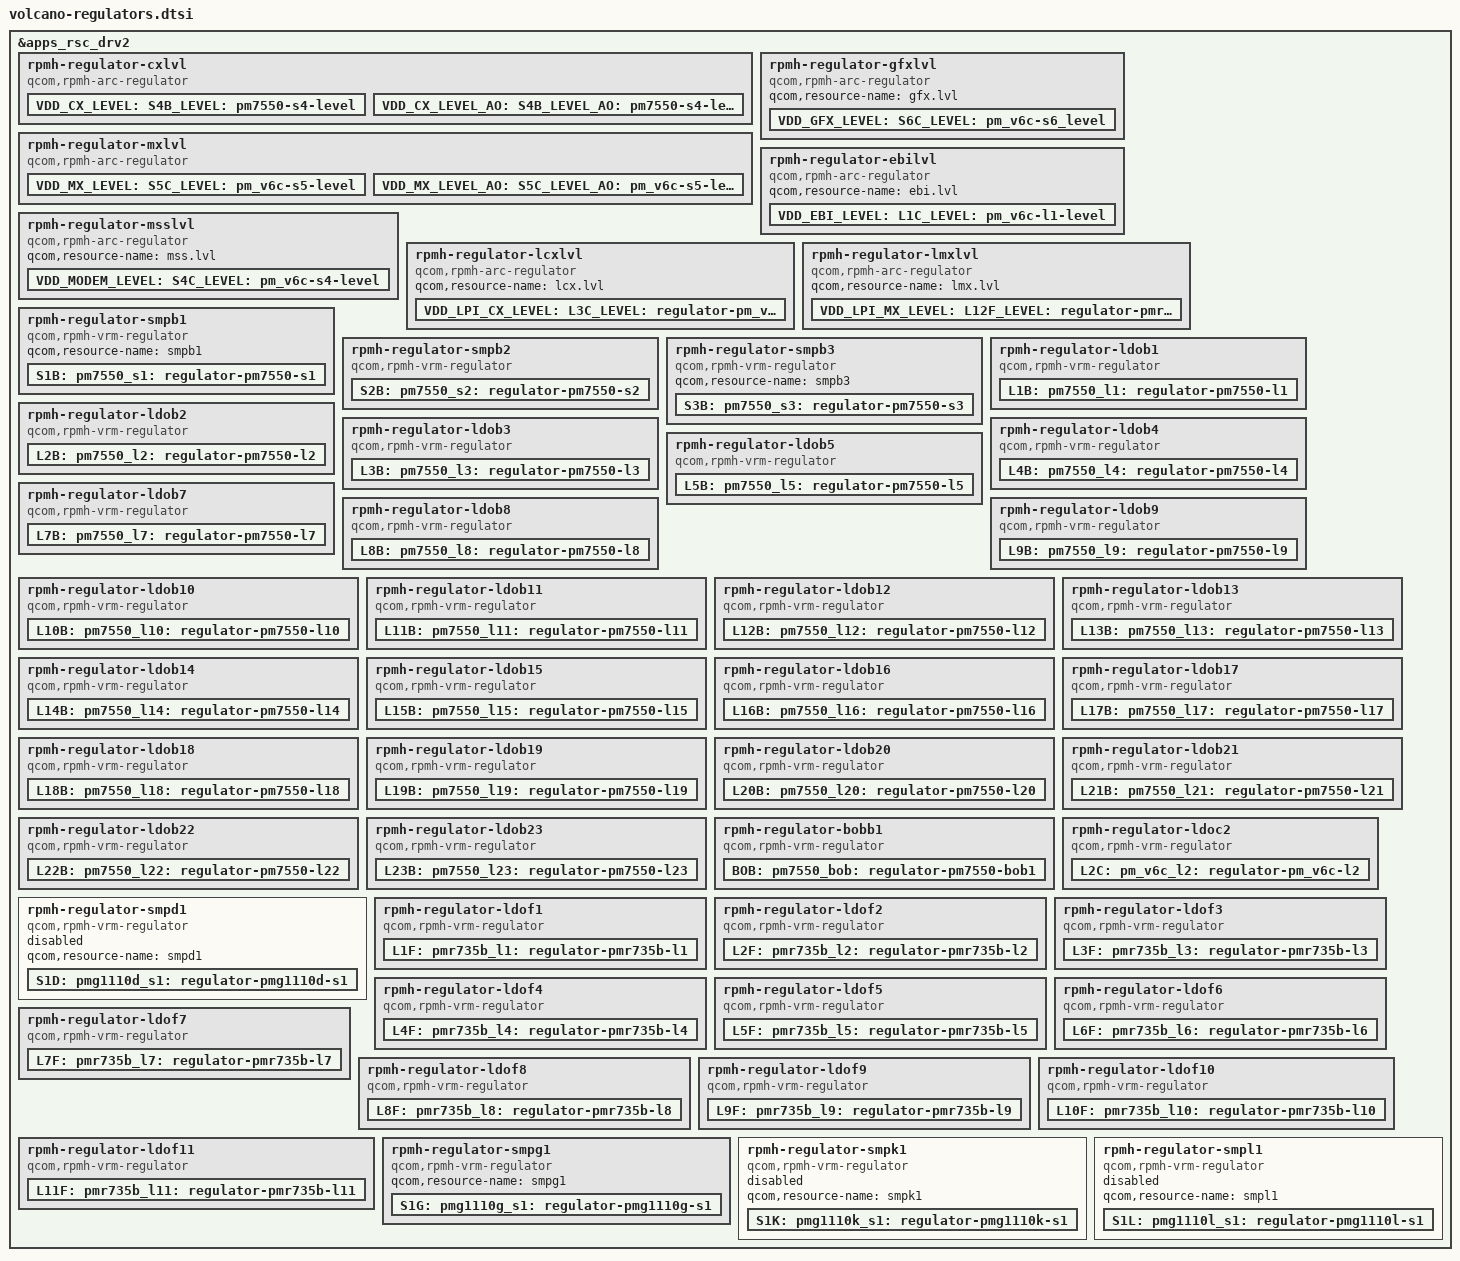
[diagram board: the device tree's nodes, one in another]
#include <dt-bindings/regulator/qcom,rpmh-regulator-levels.h>

&apps_rsc_drv2 {
	rpmh-regulator-cxlvl {
		compatible = "qcom,rpmh-arc-regulator";
		qcom,resource-name = "cx.lvl";
		proxy-supply = <&VDD_CX_LEVEL>;

		VDD_CX_LEVEL:
		S4B_LEVEL:
		pm7550_s4_level: pm7550-s4-level {
			regulator-name = "pm7550_s4_level";
			qcom,set = <RPMH_REGULATOR_SET_ALL>;
			qcom,proxy-consumer-enable;
			qcom,proxy-consumer-voltage = <RPMH_REGULATOR_LEVEL_TURBO
							RPMH_REGULATOR_LEVEL_MAX>;
			regulator-min-microvolt =
				<RPMH_REGULATOR_LEVEL_RETENTION>;
			regulator-max-microvolt = <RPMH_REGULATOR_LEVEL_MAX>;
			qcom,init-voltage-level =
				<RPMH_REGULATOR_LEVEL_TURBO>;
		};

		VDD_CX_LEVEL_AO:
		S4B_LEVEL_AO:
		pm7550_s4_level_ao: pm7550-s4-level-ao {
			regulator-name = "pm7550_s4_level_ao";
			qcom,set = <RPMH_REGULATOR_SET_ACTIVE>;
			regulator-min-microvolt =
				<RPMH_REGULATOR_LEVEL_RETENTION>;
			regulator-max-microvolt = <RPMH_REGULATOR_LEVEL_MAX>;
			qcom,init-voltage-level =
				<RPMH_REGULATOR_LEVEL_RETENTION>;
		};
	};

	rpmh-regulator-mxlvl {
		compatible = "qcom,rpmh-arc-regulator";
		qcom,resource-name = "mx.lvl";
		proxy-supply = <&VDD_MX_LEVEL>;

		VDD_MX_LEVEL:
		S5C_LEVEL:
		pm_v6c_s5_level: pm_v6c-s5-level {
			regulator-name = "pm_v6c_s5_level";
			qcom,set = <RPMH_REGULATOR_SET_ALL>;
			qcom,proxy-consumer-enable;
			qcom,proxy-consumer-voltage = <RPMH_REGULATOR_LEVEL_TURBO
							RPMH_REGULATOR_LEVEL_MAX>;
			regulator-min-microvolt =
				<RPMH_REGULATOR_LEVEL_RETENTION>;
			regulator-max-microvolt = <RPMH_REGULATOR_LEVEL_MAX>;
			qcom,init-voltage-level =
				<RPMH_REGULATOR_LEVEL_RETENTION>;
		};

		VDD_MX_LEVEL_AO:
		S5C_LEVEL_AO:
		pm_v6c_s5_level_ao: pm_v6c-s5-level-ao {
			regulator-name = "pm_v6c_s5_level_ao";
			qcom,set = <RPMH_REGULATOR_SET_ACTIVE>;
			regulator-min-microvolt =
				<RPMH_REGULATOR_LEVEL_RETENTION>;
			regulator-max-microvolt = <RPMH_REGULATOR_LEVEL_MAX>;
			qcom,init-voltage-level =
				<RPMH_REGULATOR_LEVEL_RETENTION>;
		};
	};

	rpmh-regulator-gfxlvl {
		compatible = "qcom,rpmh-arc-regulator";
		qcom,resource-name = "gfx.lvl";

		VDD_GFX_LEVEL:
		S6C_LEVEL:
		pm_v6c_s6_level: pm_v6c-s6_level {
			regulator-name = "pm_v6c_s6_level";
			qcom,set = <RPMH_REGULATOR_SET_ALL>;
			regulator-min-microvolt =
					<RPMH_REGULATOR_LEVEL_RETENTION>;
			regulator-max-microvolt = <RPMH_REGULATOR_LEVEL_MAX>;
			qcom,init-voltage-level = <RPMH_REGULATOR_LEVEL_TURBO>;
		};
	};

	rpmh-regulator-ebilvl {
		compatible = "qcom,rpmh-arc-regulator";
		qcom,resource-name = "ebi.lvl";

		VDD_EBI_LEVEL:
		L1C_LEVEL:
		pm_v6c_l1_level: pm_v6c-l1-level {
			regulator-name = "pm_v6c_l1_level";
			qcom,set = <RPMH_REGULATOR_SET_ALL>;
			regulator-min-microvolt =
				<RPMH_REGULATOR_LEVEL_RETENTION>;
			regulator-max-microvolt = <RPMH_REGULATOR_LEVEL_MAX>;
			qcom,init-voltage-level =
				<RPMH_REGULATOR_LEVEL_TURBO>;
		};
	};

	rpmh-regulator-msslvl {
		compatible = "qcom,rpmh-arc-regulator";
		qcom,resource-name = "mss.lvl";

		VDD_MODEM_LEVEL:
		S4C_LEVEL:
		pm_v6c_s4_level: pm_v6c-s4-level {
			regulator-name = "pm_v6c_s4_level";
			qcom,set = <RPMH_REGULATOR_SET_ALL>;
			regulator-min-microvolt =
				<RPMH_REGULATOR_LEVEL_RETENTION>;
			regulator-max-microvolt = <RPMH_REGULATOR_LEVEL_MAX>;
			qcom,init-voltage-level =
				<RPMH_REGULATOR_LEVEL_RETENTION>;
		};
	};

	rpmh-regulator-lcxlvl {
		compatible = "qcom,rpmh-arc-regulator";
		qcom,resource-name = "lcx.lvl";

		VDD_LPI_CX_LEVEL:
		L3C_LEVEL:
		pm_v6c_l3_level: regulator-pm_v6c-l3-level {
			regulator-name = "pm_v6c_l3_level";
			qcom,set = <RPMH_REGULATOR_SET_ALL>;
			regulator-min-microvolt =
				<RPMH_REGULATOR_LEVEL_RETENTION>;
			regulator-max-microvolt = <RPMH_REGULATOR_LEVEL_MAX>;
			qcom,init-voltage-level =
				<RPMH_REGULATOR_LEVEL_RETENTION>;
		};
	};

	rpmh-regulator-lmxlvl {
		compatible = "qcom,rpmh-arc-regulator";
		qcom,resource-name = "lmx.lvl";

		VDD_LPI_MX_LEVEL:
		L12F_LEVEL:
		pmr735b_l12_level: regulator-pmr735b-l12-level {
			regulator-name = "pmr735b_l12_level";
			qcom,set = <RPMH_REGULATOR_SET_ALL>;
			regulator-min-microvolt =
				<RPMH_REGULATOR_LEVEL_RETENTION>;
			regulator-max-microvolt = <RPMH_REGULATOR_LEVEL_MAX>;
			qcom,init-voltage-level =
				<RPMH_REGULATOR_LEVEL_RETENTION>;
		};
	};

	rpmh-regulator-smpb1 {
		compatible = "qcom,rpmh-vrm-regulator";
		qcom,resource-name = "smpb1";

		S1B:
		pm7550_s1: regulator-pm7550-s1 {
			regulator-name = "pm7550_s1";
			qcom,set = <RPMH_REGULATOR_SET_ALL>;
			regulator-min-microvolt = <1800000>;
			regulator-max-microvolt = <2080000>;
			qcom,init-voltage = <1872000>;
		};
	};

	rpmh-regulator-smpb2 {
		compatible = "qcom,rpmh-vrm-regulator";
		qcom,resource-name = "smpb2";
		qcom,regulator-type = "pmic5-ftsmps";
		qcom,supported-modes = <RPMH_REGULATOR_MODE_RET
			 RPMH_REGULATOR_MODE_HPM>;
		qcom,mode-threshold-currents = <0 200000>;

		S2B:
		pm7550_s2: regulator-pm7550-s2 {
			regulator-name = "pm7550_s2";
			qcom,set = <RPMH_REGULATOR_SET_ALL>;
			regulator-min-microvolt = <1256000>;
			regulator-max-microvolt = <1408000>;
			qcom,init-voltage = <1256000>;
			qcom,init-mode = <RPMH_REGULATOR_MODE_HPM>;
		};
	};

	rpmh-regulator-smpb3 {
		compatible = "qcom,rpmh-vrm-regulator";
		qcom,resource-name = "smpb3";

		S3B:
		pm7550_s3: regulator-pm7550-s3 {
			regulator-name = "pm7550_s3";
			qcom,set = <RPMH_REGULATOR_SET_ALL>;
			regulator-min-microvolt = <880000>;
			regulator-max-microvolt = <1040000>;
			qcom,init-voltage = <972000>;
		};
	};

	rpmh-regulator-ldob1 {
		compatible = "qcom,rpmh-vrm-regulator";
		qcom,resource-name = "ldob1";
		qcom,regulator-type = "pmic5-ldo";
		qcom,supported-modes =
			<RPMH_REGULATOR_MODE_LPM
			RPMH_REGULATOR_MODE_HPM>;
		qcom,mode-threshold-currents = <0 30000>;

		L1B:
		pm7550_l1: regulator-pm7550-l1 {
			regulator-name = "pm7550_l1";
			qcom,set = <RPMH_REGULATOR_SET_ALL>;
			regulator-min-microvolt = <1800000>;
			regulator-max-microvolt = <1800000>;
			qcom,init-voltage = <1800000>;
			qcom,init-mode = <RPMH_REGULATOR_MODE_LPM>;
			regulator-always-on;
		};
	};

	rpmh-regulator-ldob2 {
		compatible = "qcom,rpmh-vrm-regulator";
		qcom,resource-name = "ldob2";
		qcom,regulator-type = "pmic5-ldo";
		qcom,supported-modes =
			<RPMH_REGULATOR_MODE_LPM
			RPMH_REGULATOR_MODE_HPM>;
		qcom,mode-threshold-currents = <0 30000>;
		proxy-supply = <&L2B>;

		L2B:
		pm7550_l2: regulator-pm7550-l2 {
			regulator-name = "pm7550_l2";
			qcom,set = <RPMH_REGULATOR_SET_ALL>;
			regulator-min-microvolt = <880000>;
			regulator-max-microvolt = <912000>;
			qcom,init-voltage = <880000>;
			qcom,init-mode = <RPMH_REGULATOR_MODE_HPM>;
			qcom,proxy-consumer-enable;
			qcom,proxy-consumer-current = <98000>;
		};
	};

	rpmh-regulator-ldob3 {
		compatible = "qcom,rpmh-vrm-regulator";
		qcom,resource-name = "ldob3";
		qcom,regulator-type = "pmic5-ldo";
		qcom,supported-modes =
			<RPMH_REGULATOR_MODE_LPM
			RPMH_REGULATOR_MODE_HPM>;
		qcom,mode-threshold-currents = <0 30000>;

		L3B:
		pm7550_l3: regulator-pm7550-l3 {
			regulator-name = "pm7550_l3";
			qcom,set = <RPMH_REGULATOR_SET_ALL>;
			regulator-min-microvolt = <880000>;
			regulator-max-microvolt = <912000>;
			qcom,init-voltage = <880000>;
			qcom,init-mode = <RPMH_REGULATOR_MODE_HPM>;
		};
	};

	rpmh-regulator-ldob4 {
		compatible = "qcom,rpmh-vrm-regulator";
		qcom,resource-name = "ldob4";
		qcom,regulator-type = "pmic5-ldo";
		qcom,supported-modes =
			<RPMH_REGULATOR_MODE_LPM
			RPMH_REGULATOR_MODE_HPM>;
		qcom,mode-threshold-currents = <0 30000>;
		proxy-supply = <&L4B>;

		L4B:
		pm7550_l4: regulator-pm7550-l4 {
			regulator-name = "pm7550_l4";
			qcom,set = <RPMH_REGULATOR_SET_ALL>;
			regulator-min-microvolt = <1200000>;
			regulator-max-microvolt = <1200000>;
			qcom,init-voltage = <1200000>;
			qcom,init-mode = <RPMH_REGULATOR_MODE_HPM>;
			qcom,proxy-consumer-enable;
			qcom,proxy-consumer-current = <16600>;
		};
	};

	rpmh-regulator-ldob5 {
		compatible = "qcom,rpmh-vrm-regulator";
		qcom,resource-name = "ldob5";
		qcom,regulator-type = "pmic5-ldo";
		qcom,supported-modes =
			<RPMH_REGULATOR_MODE_RET
			 RPMH_REGULATOR_MODE_LPM
			 RPMH_REGULATOR_MODE_HPM>;
		qcom,mode-threshold-currents = <0 10000 30000>;

		L5B:
		pm7550_l5: regulator-pm7550-l5 {
			regulator-name = "pm7550_l5";
			qcom,set = <RPMH_REGULATOR_SET_ALL>;
			regulator-min-microvolt = <1200000>;
			regulator-max-microvolt = <1200000>;
			qcom,init-voltage = <1200000>;
			qcom,init-mode = <RPMH_REGULATOR_MODE_LPM>;
			regulator-always-on;
		};
	};

	rpmh-regulator-ldob7 {
		compatible = "qcom,rpmh-vrm-regulator";
		qcom,resource-name = "ldob7";
		qcom,regulator-type = "pmic5-ldo";
		qcom,supported-modes =
			<RPMH_REGULATOR_MODE_LPM
			RPMH_REGULATOR_MODE_HPM>;
		qcom,mode-threshold-currents = <0 30000>;

		L7B:
		pm7550_l7: regulator-pm7550-l7 {
			regulator-name = "pm7550_l7";
			qcom,set = <RPMH_REGULATOR_SET_ALL>;
			regulator-min-microvolt = <1800000>;
			regulator-max-microvolt = <1800000>;
			qcom,init-voltage = <1800000>;
			qcom,init-mode = <RPMH_REGULATOR_MODE_HPM>;
		};
	};

	rpmh-regulator-ldob8 {
		compatible = "qcom,rpmh-vrm-regulator";
		qcom,resource-name = "ldob8";
		qcom,regulator-type = "pmic5-ldo";
		qcom,supported-modes =
			<RPMH_REGULATOR_MODE_LPM
			RPMH_REGULATOR_MODE_HPM>;
		qcom,mode-threshold-currents = <0 30000>;

		L8B:
		pm7550_l8: regulator-pm7550-l8 {
			regulator-name = "pm7550_l8";
			qcom,set = <RPMH_REGULATOR_SET_ALL>;
			regulator-min-microvolt = <1800000>;
			regulator-max-microvolt = <1800000>;
			qcom,init-voltage = <1800000>;
			qcom,init-mode = <RPMH_REGULATOR_MODE_HPM>;
		};
	};

	rpmh-regulator-ldob9 {
		compatible = "qcom,rpmh-vrm-regulator";
		qcom,resource-name = "ldob9";
		qcom,regulator-type = "pmic5-ldo";
		qcom,supported-modes =
			<RPMH_REGULATOR_MODE_LPM
			RPMH_REGULATOR_MODE_HPM>;
		qcom,mode-threshold-currents = <0 30000>;
		proxy-supply = <&L9B>;

		L9B:
		pm7550_l9: regulator-pm7550-l9 {
			regulator-name = "pm7550_l9";
			qcom,set = <RPMH_REGULATOR_SET_ALL>;
			regulator-min-microvolt = <1800000>;
			regulator-max-microvolt = <1800000>;
			qcom,init-voltage = <1800000>;
			qcom,init-mode = <RPMH_REGULATOR_MODE_HPM>;
			qcom,proxy-consumer-enable;
			qcom,proxy-consumer-current = <220000>;
		};
	};

	rpmh-regulator-ldob10 {
		compatible = "qcom,rpmh-vrm-regulator";
		qcom,resource-name = "ldob10";
		qcom,regulator-type = "pmic5-ldo";
		qcom,supported-modes =
			<RPMH_REGULATOR_MODE_LPM
			RPMH_REGULATOR_MODE_HPM>;
		qcom,mode-threshold-currents = <0 30000>;

		L10B:
		pm7550_l10: regulator-pm7550-l10 {
			regulator-name = "pm7550_l10";
			qcom,set = <RPMH_REGULATOR_SET_ALL>;
			regulator-min-microvolt = <1800000>;
			regulator-max-microvolt = <1800000>;
			qcom,init-voltage = <1800000>;
			qcom,init-mode = <RPMH_REGULATOR_MODE_HPM>;
		};
	};

	rpmh-regulator-ldob11 {
		compatible = "qcom,rpmh-vrm-regulator";
		qcom,resource-name = "ldob11";
		qcom,regulator-type = "pmic5-ldo";
		qcom,supported-modes =
			<RPMH_REGULATOR_MODE_LPM
			RPMH_REGULATOR_MODE_HPM>;
		qcom,mode-threshold-currents = <0 30000>;

		L11B:
		pm7550_l11: regulator-pm7550-l11 {
			regulator-name = "pm7550_l11";
			qcom,set = <RPMH_REGULATOR_SET_ALL>;
			regulator-min-microvolt = <1800000>;
			regulator-max-microvolt = <1800000>;
			qcom,init-voltage = <1800000>;
			qcom,init-mode = <RPMH_REGULATOR_MODE_HPM>;
		};
	};

	rpmh-regulator-ldob12 {
		compatible = "qcom,rpmh-vrm-regulator";
		qcom,resource-name = "ldob12";
		qcom,regulator-type = "pmic5-ldo";
		qcom,supported-modes =
			<RPMH_REGULATOR_MODE_LPM
			RPMH_REGULATOR_MODE_HPM>;
		qcom,mode-threshold-currents = <0 10000>;

		/*
		 * This is for UFS Peripheral,which supports 2 variants
		 * UFS 3.1 ,and UFS 2.2 both require different voltages.
		 * Hence preventing voltage voting as per previous targets.
		 */

		L12B:
		pm7550_l12: regulator-pm7550-l12 {
			regulator-name = "pm7550_l12";
			qcom,set = <RPMH_REGULATOR_SET_ALL>;
			qcom,init-mode = <RPMH_REGULATOR_MODE_HPM>;
		};
	};

	rpmh-regulator-ldob13 {
		compatible = "qcom,rpmh-vrm-regulator";
		qcom,resource-name = "ldob13";
		qcom,regulator-type = "pmic5-ldo";
		qcom,supported-modes =
			<RPMH_REGULATOR_MODE_LPM
			RPMH_REGULATOR_MODE_HPM>;
		qcom,mode-threshold-currents = <0 10000>;

		L13B:
		pm7550_l13: regulator-pm7550-l13 {
			regulator-name = "pm7550_l13";
			qcom,set = <RPMH_REGULATOR_SET_ALL>;
			regulator-min-microvolt = <2700000>;
			regulator-max-microvolt = <3300000>;
			qcom,init-voltage = <2700000>;
			qcom,init-mode = <RPMH_REGULATOR_MODE_HPM>;
		};
	};

	rpmh-regulator-ldob14 {
		compatible = "qcom,rpmh-vrm-regulator";
		qcom,resource-name = "ldob14";
		qcom,regulator-type = "pmic5-ldo";
		qcom,supported-modes =
			<RPMH_REGULATOR_MODE_LPM
			RPMH_REGULATOR_MODE_HPM>;
		qcom,mode-threshold-currents = <0 10000>;

		L14B:
		pm7550_l14: regulator-pm7550-l14 {
			regulator-name = "pm7550_l14";
			qcom,set = <RPMH_REGULATOR_SET_ALL>;
			regulator-min-microvolt = <3300000>;
			regulator-max-microvolt = <3304000>;
			qcom,init-voltage = <3300000>;
			qcom,init-mode = <RPMH_REGULATOR_MODE_HPM>;
		};
	};

	rpmh-regulator-ldob15 {
		compatible = "qcom,rpmh-vrm-regulator";
		qcom,resource-name = "ldob15";
		qcom,regulator-type = "pmic5-ldo";
		qcom,supported-modes =
			<RPMH_REGULATOR_MODE_LPM
			RPMH_REGULATOR_MODE_HPM>;
		qcom,mode-threshold-currents = <0 10000>;

		L15B:
		pm7550_l15: regulator-pm7550-l15 {
			regulator-name = "pm7550_l15";
			qcom,set = <RPMH_REGULATOR_SET_ALL>;
			regulator-min-microvolt = <3300000>;
			regulator-max-microvolt = <3304000>;
			qcom,init-voltage = <3300000>;
			qcom,init-mode = <RPMH_REGULATOR_MODE_HPM>;
		};
	};

	rpmh-regulator-ldob16 {
		compatible = "qcom,rpmh-vrm-regulator";
		qcom,resource-name = "ldob16";
		qcom,regulator-type = "pmic5-ldo";
		qcom,supported-modes =
			<RPMH_REGULATOR_MODE_LPM
			RPMH_REGULATOR_MODE_HPM>;
		qcom,mode-threshold-currents = <0 10000>;

		L16B:
		pm7550_l16: regulator-pm7550-l16 {
			regulator-name = "pm7550_l16";
			qcom,set = <RPMH_REGULATOR_SET_ALL>;
			regulator-min-microvolt = <3008000>;
			regulator-max-microvolt = <3008000>;
			qcom,init-voltage = <3008000>;
			qcom,init-mode = <RPMH_REGULATOR_MODE_HPM>;
		};
	};

	rpmh-regulator-ldob17 {
		compatible = "qcom,rpmh-vrm-regulator";
		qcom,resource-name = "ldob17";
		qcom,regulator-type = "pmic5-ldo";
		qcom,supported-modes =
			<RPMH_REGULATOR_MODE_LPM
			RPMH_REGULATOR_MODE_HPM>;
		qcom,mode-threshold-currents = <0 10000>;

		L17B:
		pm7550_l17: regulator-pm7550-l17 {
			regulator-name = "pm7550_l17";
			qcom,set = <RPMH_REGULATOR_SET_ALL>;
			regulator-min-microvolt = <3104000>;
			regulator-max-microvolt = <3104000>;
			qcom,init-voltage = <3104000>;
			qcom,init-mode = <RPMH_REGULATOR_MODE_HPM>;
		};
	};

	rpmh-regulator-ldob18 {
		compatible = "qcom,rpmh-vrm-regulator";
		qcom,resource-name = "ldob18";
		qcom,regulator-type = "pmic5-ldo";
		qcom,supported-modes =
			<RPMH_REGULATOR_MODE_LPM
			RPMH_REGULATOR_MODE_HPM>;
		qcom,mode-threshold-currents = <0 10000>;

		L18B:
		pm7550_l18: regulator-pm7550-l18 {
			regulator-name = "pm7550_l18";
			qcom,set = <RPMH_REGULATOR_SET_ALL>;
			regulator-min-microvolt = <2800000>;
			regulator-max-microvolt = <2800000>;
			qcom,init-voltage = <2800000>;
			qcom,init-mode = <RPMH_REGULATOR_MODE_HPM>;
		};
	};

	rpmh-regulator-ldob19 {
		compatible = "qcom,rpmh-vrm-regulator";
		qcom,resource-name = "ldob19";
		qcom,regulator-type = "pmic5-ldo";
		qcom,supported-modes =
			<RPMH_REGULATOR_MODE_LPM
			RPMH_REGULATOR_MODE_HPM>;
		qcom,mode-threshold-currents = <0 10000>;
		proxy-supply = <&L19B>;

		L19B:
		pm7550_l19: regulator-pm7550-l19 {
			regulator-name = "pm7550_l19";
			qcom,set = <RPMH_REGULATOR_SET_ALL>;
			regulator-min-microvolt = <3000000>;
			regulator-max-microvolt = <3000000>;
			qcom,init-voltage = <3000000>;
			qcom,init-mode = <RPMH_REGULATOR_MODE_HPM>;
			qcom,proxy-consumer-enable;
			qcom,proxy-consumer-current = <10000>;
		};
	};

	rpmh-regulator-ldob20 {
		compatible = "qcom,rpmh-vrm-regulator";
		qcom,resource-name = "ldob20";
		qcom,regulator-type = "pmic5-ldo";
		qcom,supported-modes =
			<RPMH_REGULATOR_MODE_LPM
			RPMH_REGULATOR_MODE_HPM>;
		qcom,mode-threshold-currents = <0 10000>;

		L20B:
		pm7550_l20: regulator-pm7550-l20 {
			regulator-name = "pm7550_l20";
			qcom,set = <RPMH_REGULATOR_SET_ALL>;
			regulator-min-microvolt = <1620000>;
			regulator-max-microvolt = <3544000>;
			qcom,init-voltage = <1620000>;
			qcom,init-mode = <RPMH_REGULATOR_MODE_HPM>;
		};
	};

	rpmh-regulator-ldob21 {
		compatible = "qcom,rpmh-vrm-regulator";
		qcom,resource-name = "ldob21";
		qcom,regulator-type = "pmic5-ldo";
		qcom,supported-modes =
			<RPMH_REGULATOR_MODE_LPM
			RPMH_REGULATOR_MODE_HPM>;
		qcom,mode-threshold-currents = <0 10000>;

		L21B:
		pm7550_l21: regulator-pm7550-l21 {
			regulator-name = "pm7550_l21";
			qcom,set = <RPMH_REGULATOR_SET_ALL>;
			regulator-min-microvolt = <1620000>;
			regulator-max-microvolt = <3544000>;
			qcom,init-voltage = <1620000>;
			qcom,init-mode = <RPMH_REGULATOR_MODE_HPM>;
		};
	};

	rpmh-regulator-ldob22 {
		compatible = "qcom,rpmh-vrm-regulator";
		qcom,resource-name = "ldob22";
		qcom,regulator-type = "pmic5-ldo";
		qcom,supported-modes =
			<RPMH_REGULATOR_MODE_LPM
			RPMH_REGULATOR_MODE_HPM>;
		qcom,mode-threshold-currents = <0 10000>;

		L22B:
		pm7550_l22: regulator-pm7550-l22 {
			regulator-name = "pm7550_l22";
			qcom,set = <RPMH_REGULATOR_SET_ALL>;
			regulator-min-microvolt = <3200000>;
			regulator-max-microvolt = <3200000>;
			qcom,init-voltage = <3200000>;
			qcom,init-mode = <RPMH_REGULATOR_MODE_HPM>;
		};
	};

	rpmh-regulator-ldob23 {
		compatible = "qcom,rpmh-vrm-regulator";
		qcom,resource-name = "ldob23";
		qcom,regulator-type = "pmic5-ldo";
		qcom,supported-modes =
			<RPMH_REGULATOR_MODE_LPM
			RPMH_REGULATOR_MODE_HPM>;
		qcom,mode-threshold-currents = <0 1>;

		L23B:
		pm7550_l23: regulator-pm7550-l23 {
			regulator-name = "pm7550_l23";
			qcom,set = <RPMH_REGULATOR_SET_ALL>;
			regulator-min-microvolt = <1650000>;
			regulator-max-microvolt = <3544000>;
			qcom,init-voltage = <1650000>;
			qcom,init-mode = <RPMH_REGULATOR_MODE_HPM>;
		};
	};

	rpmh-regulator-bobb1 {
		compatible = "qcom,rpmh-vrm-regulator";
		qcom,resource-name = "bobb1";
		qcom,regulator-type = "pmic5-bob";
		qcom,supported-modes =
			<RPMH_REGULATOR_MODE_PASS
			RPMH_REGULATOR_MODE_LPM
			RPMH_REGULATOR_MODE_HPM>;
		qcom,mode-threshold-currents = <0 1000000 2000000>;

		BOB:
		pm7550_bob: regulator-pm7550-bob1 {
			regulator-name = "pm7550_bob";
			qcom,set = <RPMH_REGULATOR_SET_ALL>;
			regulator-min-microvolt = <3008000>;
			regulator-max-microvolt = <3960000>;
			qcom,init-voltage = <3008000>;
		};
	};

	rpmh-regulator-ldoc2 {
		compatible = "qcom,rpmh-vrm-regulator";
		qcom,resource-name = "ldoc2";
		qcom,regulator-type = "pmic5-ldo";
		qcom,supported-modes =
			<RPMH_REGULATOR_MODE_LPM
			RPMH_REGULATOR_MODE_HPM>;
		qcom,mode-threshold-currents = <0 30000>;

		L2C:
		pm_v6c_l2: regulator-pm_v6c-l2 {
			regulator-name = "pm_v6c_l2";
			qcom,set = <RPMH_REGULATOR_SET_ALL>;
			regulator-min-microvolt = <320000>;
			regulator-max-microvolt = <650000>;
			qcom,init-voltage = <504000>;
			qcom,init-mode = <RPMH_REGULATOR_MODE_HPM>;
		};
	};

	rpmh-regulator-smpd1 {
		compatible = "qcom,rpmh-vrm-regulator";
		qcom,resource-name = "smpd1";
		status = "disabled";

		S1D:
		pmg1110d_s1: regulator-pmg1110d-s1 {
			regulator-name = "pmg1110d_s1";
			qcom,set = <RPMH_REGULATOR_SET_ALL>;
			regulator-min-microvolt = <1010000>;
			regulator-max-microvolt = <1170000>;
			qcom,init-voltage = <952000>;
		};
	};

	rpmh-regulator-ldof1 {
		compatible = "qcom,rpmh-vrm-regulator";
		qcom,resource-name = "ldof1";
		qcom,regulator-type = "pmic5-ldo";
		qcom,supported-modes =
			<RPMH_REGULATOR_MODE_LPM
			RPMH_REGULATOR_MODE_HPM>;
		qcom,mode-threshold-currents = <0 30000>;

		L1F:
		pmr735b_l1: regulator-pmr735b-l1 {
			regulator-name = "pmr735b_l1";
			qcom,set = <RPMH_REGULATOR_SET_ALL>;
			regulator-min-microvolt = <852000>;
			regulator-max-microvolt = <950000>;
			qcom,init-voltage = <852000>;
			qcom,init-mode = <RPMH_REGULATOR_MODE_HPM>;
		};
	};

	rpmh-regulator-ldof2 {
		compatible = "qcom,rpmh-vrm-regulator";
		qcom,resource-name = "ldof2";
		qcom,regulator-type = "pmic5-ldo";
		qcom,supported-modes =
			<RPMH_REGULATOR_MODE_LPM
			RPMH_REGULATOR_MODE_HPM>;
		qcom,mode-threshold-currents = <0 30000>;

		L2F:
		pmr735b_l2: regulator-pmr735b-l2 {
			regulator-name = "pmr735b_l2";
			qcom,set = <RPMH_REGULATOR_SET_ALL>;
			regulator-min-microvolt = <751000>;
			regulator-max-microvolt = <824000>;
			qcom,init-voltage = <751000>;
			qcom,init-mode = <RPMH_REGULATOR_MODE_HPM>;
		};
	};

	rpmh-regulator-ldof3 {
		compatible = "qcom,rpmh-vrm-regulator";
		qcom,resource-name = "ldof3";
		qcom,regulator-type = "pmic5-ldo";
		qcom,supported-modes =
			<RPMH_REGULATOR_MODE_LPM
			RPMH_REGULATOR_MODE_HPM>;
		qcom,mode-threshold-currents = <0 30000>;

		L3F:
		pmr735b_l3: regulator-pmr735b-l3 {
			regulator-name = "pmr735b_l3";
			qcom,set = <RPMH_REGULATOR_SET_ALL>;
			regulator-min-microvolt = <650000>;
			regulator-max-microvolt = <880000>;
			qcom,init-voltage = <650000>;
			qcom,init-mode = <RPMH_REGULATOR_MODE_HPM>;
		};
	};

	rpmh-regulator-ldof4 {
		compatible = "qcom,rpmh-vrm-regulator";
		qcom,resource-name = "ldof4";
		qcom,regulator-type = "pmic5-ldo";
		qcom,supported-modes =
			<RPMH_REGULATOR_MODE_LPM
			RPMH_REGULATOR_MODE_HPM>;
		qcom,mode-threshold-currents = <0 10000>;

		L4F:
		pmr735b_l4: regulator-pmr735b-l4 {
			regulator-name = "pmr735b_l4";
			qcom,set = <RPMH_REGULATOR_SET_ALL>;
			regulator-min-microvolt = <1700000>;
			regulator-max-microvolt = <1950000>;
			qcom,init-voltage = <1800000>;
			qcom,init-mode = <RPMH_REGULATOR_MODE_HPM>;
		};
	};

	rpmh-regulator-ldof5 {
		compatible = "qcom,rpmh-vrm-regulator";
		qcom,resource-name = "ldof5";
		qcom,regulator-type = "pmic5-ldo";
		qcom,supported-modes =
			<RPMH_REGULATOR_MODE_LPM
			RPMH_REGULATOR_MODE_HPM>;
		qcom,mode-threshold-currents = <0 30000>;

		L5F:
		pmr735b_l5: regulator-pmr735b-l5 {
			regulator-name = "pmr735b_l5";
			qcom,set = <RPMH_REGULATOR_SET_ALL>;
			regulator-min-microvolt = <1140000>;
			regulator-max-microvolt = <1260000>;
			qcom,init-voltage = <1200000>;
			qcom,init-mode = <RPMH_REGULATOR_MODE_HPM>;
		};
	};

	rpmh-regulator-ldof6 {
		compatible = "qcom,rpmh-vrm-regulator";
		qcom,resource-name = "ldof6";
		qcom,regulator-type = "pmic5-ldo";
		qcom,supported-modes =
			<RPMH_REGULATOR_MODE_LPM
			RPMH_REGULATOR_MODE_HPM>;
		qcom,mode-threshold-currents = <0 30000>;
		proxy-supply = <&L6F>;

		L6F:
		pmr735b_l6: regulator-pmr735b-l6 {
			regulator-name = "pmr735b_l6";
			qcom,set = <RPMH_REGULATOR_SET_ALL>;
			regulator-min-microvolt = <1200000>;
			regulator-max-microvolt = <1200000>;
			qcom,init-voltage = <1200000>;
			qcom,init-mode = <RPMH_REGULATOR_MODE_HPM>;
			qcom,proxy-consumer-enable;
			qcom,proxy-consumer-current = <200000>;
		};
	};

	rpmh-regulator-ldof7 {
		compatible = "qcom,rpmh-vrm-regulator";
		qcom,resource-name = "ldof7";
		qcom,regulator-type = "pmic5-ldo";
		qcom,supported-modes =
			<RPMH_REGULATOR_MODE_LPM
			RPMH_REGULATOR_MODE_HPM>;
		qcom,mode-threshold-currents = <0 30000>;

		L7F:
		pmr735b_l7: regulator-pmr735b-l7 {
			regulator-name = "pmr735b_l7";
			qcom,set = <RPMH_REGULATOR_SET_ALL>;
			regulator-min-microvolt = <1080000>;
			regulator-max-microvolt = <1350000>;
			qcom,init-voltage = <1080000>;
			qcom,init-mode = <RPMH_REGULATOR_MODE_HPM>;
		};
	};

	rpmh-regulator-ldof8 {
		compatible = "qcom,rpmh-vrm-regulator";
		qcom,resource-name = "ldof8";
		qcom,regulator-type = "pmic5-ldo";
		qcom,supported-modes =
			<RPMH_REGULATOR_MODE_LPM
			RPMH_REGULATOR_MODE_HPM>;
		qcom,mode-threshold-currents = <0 30000>;

		L8F:
		pmr735b_l8: regulator-pmr735b-l8 {
			regulator-name = "pmr735b_l8";
			qcom,set = <RPMH_REGULATOR_SET_ALL>;
			regulator-min-microvolt = <1100000>;
			regulator-max-microvolt = <1320000>;
			qcom,init-voltage = <1200000>;
			qcom,init-mode = <RPMH_REGULATOR_MODE_HPM>;
		};
	};

	rpmh-regulator-ldof9 {
		compatible = "qcom,rpmh-vrm-regulator";
		qcom,resource-name = "ldof9";
		qcom,regulator-type = "pmic5-ldo";
		qcom,supported-modes =
			<RPMH_REGULATOR_MODE_LPM
			RPMH_REGULATOR_MODE_HPM>;
		qcom,mode-threshold-currents = <0 30000>;

		L9F:
		pmr735b_l9: regulator-pmr735b-l9 {
			regulator-name = "pmr735b_l9";
			qcom,set = <RPMH_REGULATOR_SET_ALL>;
			regulator-min-microvolt = <870000>;
			regulator-max-microvolt = <970000>;
			qcom,init-voltage = <904000>;
			qcom,init-mode = <RPMH_REGULATOR_MODE_HPM>;
		};
	};

	rpmh-regulator-ldof10 {
		compatible = "qcom,rpmh-vrm-regulator";
		qcom,resource-name = "ldof10";
		qcom,regulator-type = "pmic5-ldo";
		qcom,supported-modes =
			<RPMH_REGULATOR_MODE_LPM
			RPMH_REGULATOR_MODE_HPM>;
		qcom,mode-threshold-currents = <0 10000>;

		L10F:
		pmr735b_l10: regulator-pmr735b-l10 {
			regulator-name = "pmr735b_l10";
			qcom,set = <RPMH_REGULATOR_SET_ALL>;
			regulator-min-microvolt = <1500000>;
			regulator-max-microvolt = <1800000>;
			qcom,init-voltage = <1500000>;
			qcom,init-mode = <RPMH_REGULATOR_MODE_HPM>;
		};
	};

	rpmh-regulator-ldof11 {
		compatible = "qcom,rpmh-vrm-regulator";
		qcom,resource-name = "ldof11";
		qcom,regulator-type = "pmic5-ldo";
		qcom,supported-modes =
			<RPMH_REGULATOR_MODE_LPM
			RPMH_REGULATOR_MODE_HPM>;
		qcom,mode-threshold-currents = <0 30000>;

		L11F:
		pmr735b_l11: regulator-pmr735b-l11 {
			regulator-name = "pmr735b_l11";
			qcom,set = <RPMH_REGULATOR_SET_ALL>;
			regulator-min-microvolt = <320000>;
			regulator-max-microvolt = <864000>;
			qcom,init-voltage = <320000>;
			qcom,init-mode = <RPMH_REGULATOR_MODE_HPM>;
		};
	};

	rpmh-regulator-smpg1 {
		compatible = "qcom,rpmh-vrm-regulator";
		qcom,resource-name = "smpg1";

		S1G:
		pmg1110g_s1: regulator-pmg1110g-s1 {
			regulator-name = "pmg1110g_s1";
			qcom,set = <RPMH_REGULATOR_SET_ALL>;
			regulator-min-microvolt = <1010000>;
			regulator-max-microvolt = <1170000>;
			qcom,init-voltage = <1112000>;
		};
	};

	rpmh-regulator-smpk1 {
		compatible = "qcom,rpmh-vrm-regulator";
		qcom,resource-name = "smpk1";
		status = "disabled";

		S1K:
		pmg1110k_s1: regulator-pmg1110k-s1 {
			regulator-name = "pmg1110k_s1";
			qcom,set = <RPMH_REGULATOR_SET_ALL>;
			regulator-min-microvolt = <300000>;
			regulator-max-microvolt = <1004000>;
			qcom,init-voltage = <300000>;
		};
	};

	rpmh-regulator-smpl1 {
		compatible = "qcom,rpmh-vrm-regulator";
		qcom,resource-name = "smpl1";
		status = "disabled";

		S1L:
		pmg1110l_s1: regulator-pmg1110l-s1 {
			regulator-name = "pmg1110l_s1";
			qcom,set = <RPMH_REGULATOR_SET_ALL>;
			regulator-min-microvolt = <300000>;
			regulator-max-microvolt = <1004000>;
			qcom,init-voltage = <300000>;
		};
	};
};
